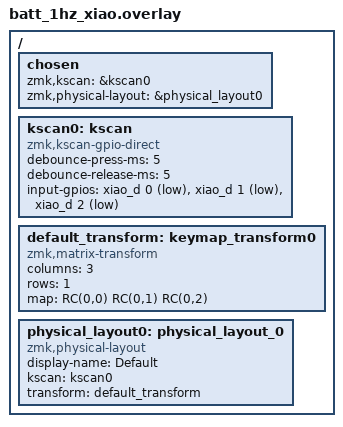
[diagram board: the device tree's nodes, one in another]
#include <dt-bindings/zmk/matrix_transform.h>

/ {
    chosen {
        zmk,kscan = &kscan0;
        zmk,physical-layout = &physical_layout0;
    };

    /*
     * Battery soak: stacked XIAO RP2040 "finger"
     *   D0 → RIGHT, D1 → LEFT, D2 → ENTER
     * Pattern: (R L)×4, R, Enter → soak_status types the time/power line.
     * Share GND + D0–D2 only (do not tie 3V3/5V/BAT).
     */
    kscan0: kscan {
        compatible = "zmk,kscan-gpio-direct";
        debounce-press-ms = <5>;
        debounce-release-ms = <5>;
        input-gpios
            = <&xiao_d 0 (GPIO_ACTIVE_LOW | GPIO_PULL_UP)>
            , <&xiao_d 1 (GPIO_ACTIVE_LOW | GPIO_PULL_UP)>
            , <&xiao_d 2 (GPIO_ACTIVE_LOW | GPIO_PULL_UP)>
            ;
    };

    default_transform: keymap_transform0 {
        compatible = "zmk,matrix-transform";
        columns = <3>;
        rows = <1>;
        map = <
            RC(0,0) RC(0,1) RC(0,2)
        >;
    };

    physical_layout0: physical_layout_0 {
        compatible = "zmk,physical-layout";
        display-name = "Default";
        kscan = <&kscan0>;
        transform = <&default_transform>;
    };
};
